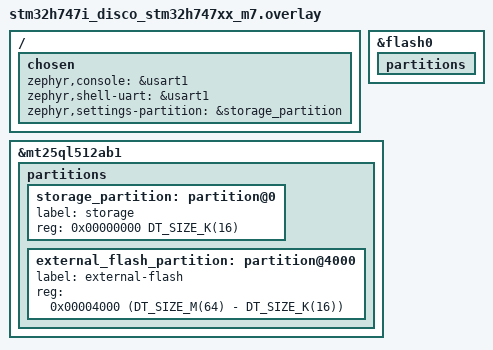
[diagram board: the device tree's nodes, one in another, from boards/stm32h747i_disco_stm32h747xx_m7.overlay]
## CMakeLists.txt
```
cmake_minimum_required(VERSION 3.20.0)
find_package(Zephyr REQUIRED HINTS $ENV{ZEPHYR_BASE})
project(industrial_ethernet)

target_include_directories(app PRIVATE
  src/core
  src/net
  src/protocols/eip
  src/protocols/modbus
  src/ui
  src/web
)

target_sources(app PRIVATE
  src/core/main.c
  src/core/ident.c
  src/net/net_cfg.c
  src/shell/util_cmds.c
  src/protocols/modbus/app_modbus_tcp.c
  src/protocols/modbus/app_modbus_scanner.c
  src/ui/app_lcd.c
  src/web/app_web.c
)

add_subdirectory(src/protocols/eip)
```

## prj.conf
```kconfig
# Phase 1: Network connectivity
CONFIG_NETWORKING=y
CONFIG_NET_IPV4=y
CONFIG_NET_IPV6=y
CONFIG_NET_IPV6_ND=y
CONFIG_NET_IPV6_DAD=y
CONFIG_NET_IPV6_MLD=y
CONFIG_NET_TCP=y
CONFIG_NET_UDP=y
CONFIG_NET_DHCPV4=y
CONFIG_NET_L2_ETHERNET=y
CONFIG_NET_SOCKETS=y
CONFIG_NET_SHELL=n
CONFIG_NET_STATISTICS=n
CONFIG_NET_BUF_POOL_USAGE=n

# Network buffers
CONFIG_NET_PKT_RX_COUNT=16
CONFIG_NET_PKT_TX_COUNT=16
CONFIG_NET_BUF_RX_COUNT=32
CONFIG_NET_BUF_TX_COUNT=32
CONFIG_NET_MAX_CONTEXTS=24
# Modbus, Web, EIP listeners and their concurrent accepted connections.
CONFIG_NET_MAX_CONN=16
# OpENer: 3 listeners + 6 explicit sessions + 1 implicit I/O socket
CONFIG_ZVFS_POLL_MAX=10

# Network events
CONFIG_NET_MGMT_EVENT_INFO=y
CONFIG_NET_MGMT_EVENT_STACK_SIZE=2048
CONFIG_NET_ARP_GRATUITOUS_TRANSMISSION=y

# Modbus TCP server
CONFIG_MODBUS=y
CONFIG_MODBUS_ROLE_SERVER=y
CONFIG_MODBUS_RAW_ADU=y
CONFIG_MODBUS_NUMOF_RAW_ADU=2
CONFIG_MODBUS_FP_EXTENSIONS=n
CONFIG_MODBUS_LOG_LEVEL_INF=y

# Logging
CONFIG_LOG=y
CONFIG_LOG_MODE_IMMEDIATE=y

# Shell
CONFIG_SHELL=y
CONFIG_KERNEL_SHELL=y
CONFIG_REBOOT=y

# Main stack size
CONFIG_MAIN_STACK_SIZE=4096

# GPIO for LED heartbeat
CONFIG_GPIO=y
CONFIG_HWINFO=y

# Settings stored in external QSPI NOR through the settings/NVS backend
CONFIG_SETTINGS=y
CONFIG_NVS=y
CONFIG_SETTINGS_NVS=y
CONFIG_SETTINGS_NVS_SECTOR_COUNT=2
CONFIG_NVS_INIT_BAD_MEMORY_REGION=y
CONFIG_FLASH=y
CONFIG_FLASH_MAP=y
CONFIG_FLASH_PAGE_LAYOUT=y
CONFIG_FLASH_STM32_QSPI=y
```

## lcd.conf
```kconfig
# Phase 5: local LVGL dashboard on the M7-owned DSI display
CONFIG_DISPLAY=y
CONFIG_DISPLAY_LOG_LEVEL_ERR=y
CONFIG_INPUT=y
CONFIG_LVGL=y
CONFIG_LV_Z_MEM_POOL_SIZE=32768
CONFIG_LV_USE_LABEL=y
CONFIG_LV_USE_BAR=y
CONFIG_LV_USE_BUTTON=y
CONFIG_LV_FONT_MONTSERRAT_14=y
CONFIG_LV_FONT_MONTSERRAT_20=y
CONFIG_LV_FONT_MONTSERRAT_24=y
```

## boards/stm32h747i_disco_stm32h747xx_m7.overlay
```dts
/* Phase 1: Ethernet is already enabled in the board DTS.
 * This overlay is a placeholder for future partition layout and peripheral config.
 */

/ {
	chosen {
		zephyr,console = &usart1;
		zephyr,shell-uart = &usart1;
		zephyr,settings-partition = &storage_partition;
	};
};

&flash0 {
	partitions {
		/delete-node/ partition@ff800;
	};
};

/* Store settings in the external QSPI NOR so the full internal flash0 remains
 * available for the M7 application image.
 */
&mt25ql512ab1 {
	partitions {
		/delete-node/ partition@0;

		storage_partition: partition@0 {
			label = "storage";
			reg = <0x00000000 DT_SIZE_K(16)>;
		};

		external_flash_partition: partition@4000 {
			label = "external-flash";
			reg = <0x00004000 (DT_SIZE_M(64) - DT_SIZE_K(16))>;
		};
	};
};
```

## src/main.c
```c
/*
 * Phase 1: DHCP/static IPv4, ping support and LED heartbeat.
 * Target: STM32H747I-DISCO Cortex-M7.
 */

#include <zephyr/kernel.h>
#include <zephyr/net/net_if.h>
#include <zephyr/net/net_mgmt.h>
#include <zephyr/net/net_event.h>
#include <zephyr/net/net_ip.h>
#include <zephyr/drivers/gpio.h>
#include <zephyr/settings/settings.h>
#include <zephyr/logging/log.h>

#include "app_modbus_tcp.h"
#include "net_cfg.h"

LOG_MODULE_REGISTER(main, LOG_LEVEL_INF);

static const struct gpio_dt_spec led = GPIO_DT_SPEC_GET(DT_ALIAS(led0), gpios);
static struct net_mgmt_event_callback mgmt_cb;

static void net_event_handler(struct net_mgmt_event_callback *cb,
			      uint64_t mgmt_event, struct net_if *iface)
{
	struct net_if_config *cfg;
	struct net_if_addr *dhcp_addr = NULL;

	ARG_UNUSED(cb);

	if (mgmt_event != NET_EVENT_IPV4_DHCP_BOUND) {
		return;
	}

	cfg = net_if_get_config(iface);
	for (int i = 0; i < NET_IF_MAX_IPV4_ADDR; i++) {
		struct net_if_addr *ifaddr = &cfg->ip.ipv4->unicast[i].ipv4;

		if (ifaddr->is_used && ifaddr->addr_type == NET_ADDR_DHCP) {
			dhcp_addr = ifaddr;
			break;
		}
	}

	if (dhcp_addr) {
		char addr_str[NET_IPV4_ADDR_LEN];

		net_addr_ntop(AF_INET, &dhcp_addr->address.in_addr,
			      addr_str, sizeof(addr_str));
		LOG_INF("DHCP bound: %s", addr_str);
	}
}

int main(void)
{
	struct net_if *iface;
	int ret;

	LOG_INF("=== H747 Demo Phase 1 ===");

	if (!gpio_is_ready_dt(&led)) {
		LOG_ERR("LED device not ready");
		return -1;
	}
	gpio_pin_configure_dt(&led, GPIO_OUTPUT_ACTIVE);

	net_mgmt_init_event_callback(&mgmt_cb, net_event_handler,
				     NET_EVENT_IPV4_DHCP_BOUND);
	net_mgmt_add_event_callback(&mgmt_cb);

	ret = settings_subsys_init();
	if (ret < 0) {
		LOG_ERR("settings_subsys_init failed: %d", ret);
	} else {
		ret = net_cfg_load();
		if (ret < 0) {
			LOG_ERR("net_cfg_load failed: %d", ret);
		}
	}

	iface = net_if_get_default();
	if (!iface) {
		LOG_ERR("No network interface found");
		return -1;
	}

	ret = net_cfg_apply(iface);
	if (ret < 0) {
		LOG_ERR("net_cfg_apply failed: %d", ret);
	}

	ret = app_modbus_tcp_start();
	if (ret < 0) {
		LOG_ERR("app_modbus_tcp_start failed: %d", ret);
	}

	while (1) {
		gpio_pin_toggle_dt(&led);
		app_modbus_tcp_heartbeat_tick();
		k_msleep(500);
	}

	return 0;
}
```

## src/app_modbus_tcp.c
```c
/*
 * Modbus TCP server.
 *
 * The Zephyr Modbus server handles standard function codes through the
 * callbacks below. TCP framing is provided here through a RAW ADU backend.
 */

#include <errno.h>
#include <string.h>

#include <zephyr/kernel.h>
#include <zephyr/logging/log.h>
#include <zephyr/modbus/modbus.h>
#include <zephyr/net/socket.h>
#include <zephyr/sys/byteorder.h>
#include <zephyr/sys/util.h>

#include "app_modbus_tcp.h"
#include "modbus_map.h"
#include "net_cfg.h"

LOG_MODULE_REGISTER(app_modbus_tcp, LOG_LEVEL_INF);

#define APP_MODBUS_TCP_PORT 502
#define APP_MODBUS_UNIT_ID 1
#define APP_MODBUS_THREAD_STACK_SIZE 4096
#define APP_MODBUS_THREAD_PRIORITY 7

#define APP_MODBUS_FC23_READ_WRITE_REGS 0x17
#define APP_MODBUS_TCP_BACKLOG 2
#define APP_MODBUS_RAW_TIMEOUT_MS 1000

static uint16_t holding_regs[APP_MODBUS_HOLDING_REG_COUNT] = {
	[0] = 0x0747,
	[1] = 1,
};

static struct modbus_adu tcp_adu;
static K_SEM_DEFINE(raw_response_ready, 0, 1);
static int server_iface = -1;
static bool server_started;
static uint16_t connection_count;
static uint16_t heartbeat_counter;
static int16_t last_status;

K_THREAD_STACK_DEFINE(modbus_tcp_stack, APP_MODBUS_THREAD_STACK_SIZE);
static struct k_thread modbus_tcp_thread;
static k_tid_t modbus_tcp_tid;

static uint16_t ipv4_word_msw(const char *ip)
{
	struct in_addr addr;
	uint32_t host_addr;

	if (net_addr_pton(AF_INET, ip, &addr) < 0) {
		return 0;
	}

	host_addr = ntohl(addr.s_addr);
	return (uint16_t)(host_addr >> 16);
}

static uint16_t ipv4_word_lsw(const char *ip)
{
	struct in_addr addr;
	uint32_t host_addr;

	if (net_addr_pton(AF_INET, ip, &addr) < 0) {
		return 0;
	}

	host_addr = ntohl(addr.s_addr);
	return (uint16_t)(host_addr & 0xffffU);
}

static void ipv4_words_to_string(uint16_t msw, uint16_t lsw, char *dst, size_t dst_len)
{
	uint32_t host_addr = ((uint32_t)msw << 16) | lsw;
	struct in_addr addr = {
		.s_addr = htonl(host_addr),
	};

	net_addr_ntop(AF_INET, &addr, dst, dst_len);
}

static void sync_holding_regs_from_saved_cfg(void)
{
	struct net_cfg_data saved;

	if (net_cfg_get_saved(&saved) < 0) {
		return;
	}

	holding_regs[APP_MB_HREG_SIGNATURE] = 0x0747;
	holding_regs[APP_MB_HREG_MODE] = (uint16_t)saved.mode;
	holding_regs[APP_MB_HREG_IP_MSW] = ipv4_word_msw(saved.ip);
	holding_regs[APP_MB_HREG_IP_LSW] = ipv4_word_lsw(saved.ip);
	holding_regs[APP_MB_HREG_MASK_MSW] = ipv4_word_msw(saved.mask);
	holding_regs[APP_MB_HREG_MASK_LSW] = ipv4_word_lsw(saved.mask);
	holding_regs[APP_MB_HREG_GW_MSW] = ipv4_word_msw(saved.gw);
	holding_regs[APP_MB_HREG_GW_LSW] = ipv4_word_lsw(saved.gw);
}

static int apply_holding_regs_command(uint16_t command)
{
	struct net_cfg_data saved = { 0 };
	int ret;

	if (command == APP_MB_CMD_NONE) {
		return 0;
	}

	if (holding_regs[APP_MB_HREG_MODE] > NET_CFG_STATIC) {
		return -EINVAL;
	}

	saved.mode = (enum net_cfg_mode)holding_regs[APP_MB_HREG_MODE];
	ipv4_words_to_string(holding_regs[APP_MB_HREG_IP_MSW],
			     holding_regs[APP_MB_HREG_IP_LSW],
			     saved.ip, sizeof(saved.ip));
	ipv4_words_to_string(holding_regs[APP_MB_HREG_MASK_MSW],
			     holding_regs[APP_MB_HREG_MASK_LSW],
			     saved.mask, sizeof(saved.mask));
	ipv4_words_to_string(holding_regs[APP_MB_HREG_GW_MSW],
			     holding_regs[APP_MB_HREG_GW_LSW],
			     saved.gw, sizeof(saved.gw));

	ret = net_cfg_set_saved(&saved);
	if (ret < 0) {
		return ret;
	}

	if (command == APP_MB_CMD_SAVE_APPLY) {
		ret = net_cfg_apply(NULL);
		if (ret < 0) {
			return ret;
		}
	}

	return 0;
}

static int input_reg_rd(uint16_t addr, uint16_t *reg)
{
	struct net_cfg_data active = { 0 };
	uint32_t uptime_s = (uint32_t)(k_uptime_get() / 1000);

	if (addr >= APP_MODBUS_INPUT_REG_COUNT) {
		return -ENOTSUP;
	}

	(void)net_cfg_get_active(&active);

	switch (addr) {
	case APP_MB_IREG_SIGNATURE:
		*reg = 0x0747;
		break;
	case APP_MB_IREG_MAP_VERSION:
		*reg = APP_MODBUS_MAP_VERSION;
		break;
	case APP_MB_IREG_UPTIME_LSW:
		*reg = (uint16_t)(uptime_s & 0xffffU);
		break;
	case APP_MB_IREG_UPTIME_MSW:
		*reg = (uint16_t)(uptime_s >> 16);
		break;
	case APP_MB_IREG_ACTIVE_MODE:
		*reg = (uint16_t)active.mode;
		break;
	case APP_MB_IREG_LINK_STATUS:
		*reg = net_cfg_link_is_up() ? 1U : 0U;
		break;
	case APP_MB_IREG_IP_MSW:
		*reg = ipv4_word_msw(active.ip);
		break;
	case APP_MB_IREG_IP_LSW:
		*reg = ipv4_word_lsw(active.ip);
		break;
	case APP_MB_IREG_MASK_MSW:
		*reg = ipv4_word_msw(active.mask);
		break;
	case APP_MB_IREG_MASK_LSW:
		*reg = ipv4_word_lsw(active.mask);
		break;
	case APP_MB_IREG_GW_MSW:
		*reg = ipv4_word_msw(active.gw);
		break;
	case APP_MB_IREG_GW_LSW:
		*reg = ipv4_word_lsw(active.gw);
		break;
	case APP_MB_IREG_HEARTBEAT_LSW:
		*reg = heartbeat_counter;
		break;
	case APP_MB_IREG_LAST_STATUS:
		*reg = (uint16_t)last_status;
		break;
	case APP_MB_IREG_CONN_COUNT:
		*reg = connection_count;
		break;
	default:
		*reg = 0;
		break;
	}

	return 0;
}

static int holding_reg_rd(uint16_t addr, uint16_t *reg)
{
	if (addr >= APP_MODBUS_HOLDING_REG_COUNT) {
		return -ENOTSUP;
	}

	sync_holding_regs_from_saved_cfg();
	*reg = holding_regs[addr];
	return 0;
}

static int holding_reg_wr(uint16_t addr, uint16_t reg)
{
	int ret;

	if (addr >= APP_MODBUS_HOLDING_REG_COUNT) {
		return -ENOTSUP;
	}

	holding_regs[addr] = reg;

	if (addr == APP_MB_HREG_COMMAND) {
		ret = apply_holding_regs_command(reg);
		last_status = (int16_t)ret;
		holding_regs[APP_MB_HREG_STATUS] = (uint16_t)ret;
		holding_regs[APP_MB_HREG_COMMAND] = APP_MB_CMD_NONE;

		if (ret == 0) {
			sync_holding_regs_from_saved_cfg();
		}
	}

	return 0;
}

static bool fc23_read_write_holding_regs(const int iface,
					 const struct modbus_adu *const rx_adu,
					 struct modbus_adu *const tx_adu,
					 uint8_t *const excep_code,
					 void *const user_data)
{
	uint16_t read_addr;
	uint16_t read_qty;
	uint16_t write_addr;
	uint16_t write_qty;
	uint8_t write_bytes;
	uint8_t response_bytes;

	ARG_UNUSED(iface);
	ARG_UNUSED(user_data);

	if (rx_adu->length < 9) {
		*excep_code = MODBUS_EXC_ILLEGAL_DATA_VAL;
		return true;
	}

	read_addr = sys_get_be16(&rx_adu->data[0]);
	read_qty = sys_get_be16(&rx_adu->data[2]);
	write_addr = sys_get_be16(&rx_adu->data[4]);
	write_qty = sys_get_be16(&rx_adu->data[6]);
	write_bytes = rx_adu->data[8];

	if (read_qty == 0 || read_qty > 125 ||
	    write_qty == 0 || write_qty > 121 ||
	    write_bytes != write_qty * sizeof(uint16_t) ||
	    rx_adu->length != 9 + write_bytes) {
		*excep_code = MODBUS_EXC_ILLEGAL_DATA_VAL;
		return true;
	}

	for (uint16_t i = 0; i < write_qty; i++) {
		uint16_t reg = sys_get_be16(&rx_adu->data[9 + (i * sizeof(uint16_t))]);

		if (holding_reg_wr(write_addr + i, reg) != 0) {
			*excep_code = MODBUS_EXC_ILLEGAL_DATA_ADDR;
			return true;
		}
	}

	response_bytes = read_qty * sizeof(uint16_t);
	tx_adu->data[0] = response_bytes;
	tx_adu->length = response_bytes + 1;

	for (uint16_t i = 0; i < read_qty; i++) {
		uint16_t reg;

		if (holding_reg_rd(read_addr + i, &reg) != 0) {
			*excep_code = MODBUS_EXC_ILLEGAL_DATA_ADDR;
			return true;
		}

		sys_put_be16(reg, &tx_adu->data[1 + (i * sizeof(uint16_t))]);
	}

	return true;
}

MODBUS_CUSTOM_FC_DEFINE(fc23, fc23_read_write_holding_regs,
			APP_MODBUS_FC23_READ_WRITE_REGS, NULL);

static struct modbus_user_callbacks server_callbacks = {
	.input_reg_rd = input_reg_rd,
	.holding_reg_rd = holding_reg_rd,
	.holding_reg_wr = holding_reg_wr,
};

static int raw_tx_cb(const int iface, const struct modbus_adu *adu, void *user_data)
{
	ARG_UNUSED(iface);
	ARG_UNUSED(user_data);

	tcp_adu.trans_id = adu->trans_id;
	tcp_adu.proto_id = adu->proto_id;
	tcp_adu.length = adu->length;
	tcp_adu.unit_id = adu->unit_id;
	tcp_adu.fc = adu->fc;
	memcpy(tcp_adu.data, adu->data, MIN(adu->length, sizeof(tcp_adu.data)));

	k_sem_give(&raw_response_ready);
	return 0;
}

static const struct modbus_iface_param server_param = {
	.mode = MODBUS_MODE_RAW,
	.server = {
		.user_cb = &server_callbacks,
		.unit_id = APP_MODBUS_UNIT_ID,
	},
	.rawcb = {
		.raw_tx_cb = raw_tx_cb,
		.user_data = NULL,
	},
};

static int init_modbus_server(void)
{
	int ret;

	sync_holding_regs_from_saved_cfg();
	holding_regs[APP_MB_HREG_STATUS] = 0;

	server_iface = modbus_iface_get_by_name("RAW_0");
	if (server_iface < 0) {
		LOG_ERR("Failed to get RAW_0 Modbus interface: %d", server_iface);
		return server_iface;
	}

	ret = modbus_init_server(server_iface, server_param);
	if (ret < 0) {
		LOG_ERR("modbus_init_server failed: %d", ret);
		return ret;
	}

	ret = modbus_register_user_fc(server_iface, &modbus_cfg_fc23);
	if (ret < 0) {
		LOG_ERR("Failed to register FC23 handler: %d", ret);
		return ret;
	}

	LOG_INF("Modbus server ready: unit=%d, holding=%d, input=%d",
		APP_MODBUS_UNIT_ID, APP_MODBUS_HOLDING_REG_COUNT,
		APP_MODBUS_INPUT_REG_COUNT);
	return 0;
}

static int send_all(int client, const void *buf, size_t len)
{
	const uint8_t *cursor = buf;

	while (len > 0) {
		int ret = zsock_send(client, cursor, len, 0);

		if (ret < 0) {
			return -errno;
		}
		if (ret == 0) {
			return -ENOTCONN;
		}

		cursor += ret;
		len -= ret;
	}

	return 0;
}

static int send_modbus_reply(int client, const struct modbus_adu *adu)
{
	uint8_t header[MODBUS_MBAP_AND_FC_LENGTH];
	int ret;

	modbus_raw_put_header(adu, header);

	ret = send_all(client, header, sizeof(header));
	if (ret < 0) {
		return ret;
	}

	ret = send_all(client, adu->data, adu->length);
	if (ret < 0) {
		return ret;
	}

	return 0;
}

static int handle_modbus_connection(int client)
{
	uint8_t header[MODBUS_MBAP_AND_FC_LENGTH];
	int ret;

	ret = zsock_recv(client, header, sizeof(header), ZSOCK_MSG_WAITALL);
	if (ret <= 0) {
		return ret == 0 ? -ENOTCONN : -errno;
	}

	modbus_raw_get_header(&tcp_adu, header);
	if (tcp_adu.length > sizeof(tcp_adu.data)) {
		return -EMSGSIZE;
	}

	ret = zsock_recv(client, tcp_adu.data, tcp_adu.length, ZSOCK_MSG_WAITALL);
	if (ret <= 0) {
		return ret == 0 ? -ENOTCONN : -errno;
	}

	k_sem_reset(&raw_response_ready);
	ret = modbus_raw_submit_rx(server_iface, &tcp_adu);
	if (ret < 0) {
		LOG_ERR("modbus_raw_submit_rx failed: %d", ret);
		return ret;
	}

	if (k_sem_take(&raw_response_ready, K_MSEC(APP_MODBUS_RAW_TIMEOUT_MS)) != 0) {
		LOG_ERR("Modbus response timeout");
		modbus_raw_set_server_failure(&tcp_adu);
	}

	return send_modbus_reply(client, &tcp_adu);
}

static void modbus_tcp_thread_fn(void *arg1, void *arg2, void *arg3)
{
	struct sockaddr_in bind_addr = {
		.sin_family = AF_INET,
		.sin_addr.s_addr = htonl(INADDR_ANY),
		.sin_port = htons(APP_MODBUS_TCP_PORT),
	};
	int server;

	ARG_UNUSED(arg1);
	ARG_UNUSED(arg2);
	ARG_UNUSED(arg3);

	server = zsock_socket(AF_INET, SOCK_STREAM, IPPROTO_TCP);
	if (server < 0) {
		LOG_ERR("socket failed: %d", errno);
		return;
	}

	if (zsock_bind(server, (struct net_sockaddr *)&bind_addr, sizeof(bind_addr)) < 0) {
		LOG_ERR("bind port %d failed: %d", APP_MODBUS_TCP_PORT, errno);
		(void)zsock_close(server);
		return;
	}

	if (zsock_listen(server, APP_MODBUS_TCP_BACKLOG) < 0) {
		LOG_ERR("listen failed: %d", errno);
		(void)zsock_close(server);
		return;
	}

	LOG_INF("Modbus TCP listening on port %d", APP_MODBUS_TCP_PORT);

	while (true) {
		struct sockaddr_in client_addr;
		net_socklen_t client_addr_len = sizeof(client_addr);
		int client;
		int ret;

		client = zsock_accept(server, (struct net_sockaddr *)&client_addr,
				      &client_addr_len);
		if (client < 0) {
			LOG_ERR("accept failed: %d", errno);
			continue;
		}

		connection_count++;
		do {
			ret = handle_modbus_connection(client);
		} while (ret == 0);

		(void)zsock_close(client);
	}
}

int app_modbus_tcp_start(void)
{
	int ret;

	if (server_started) {
		return 0;
	}

	ret = init_modbus_server();
	if (ret < 0) {
		return ret;
	}

	modbus_tcp_tid = k_thread_create(&modbus_tcp_thread, modbus_tcp_stack,
					 K_THREAD_STACK_SIZEOF(modbus_tcp_stack),
					 modbus_tcp_thread_fn,
					 NULL, NULL, NULL,
					 APP_MODBUS_THREAD_PRIORITY, 0, K_NO_WAIT);
	k_thread_name_set(modbus_tcp_tid, "modbus_tcp");

	server_started = true;
	return 0;
}

void app_modbus_tcp_heartbeat_tick(void)
{
	heartbeat_counter++;
}
```

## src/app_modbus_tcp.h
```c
#ifndef APP_MODBUS_TCP_H_
#define APP_MODBUS_TCP_H_

int app_modbus_tcp_start(void);
void app_modbus_tcp_heartbeat_tick(void);

#endif /* APP_MODBUS_TCP_H_ */
```

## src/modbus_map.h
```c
#ifndef MODBUS_MAP_H_
#define MODBUS_MAP_H_

#define APP_MODBUS_MAP_VERSION 1

#define APP_MODBUS_HOLDING_REG_COUNT 32
#define APP_MODBUS_INPUT_REG_COUNT 16

#define APP_MB_HREG_SIGNATURE 0
#define APP_MB_HREG_MODE 1
#define APP_MB_HREG_IP_MSW 2
#define APP_MB_HREG_IP_LSW 3
#define APP_MB_HREG_MASK_MSW 4
#define APP_MB_HREG_MASK_LSW 5
#define APP_MB_HREG_GW_MSW 6
#define APP_MB_HREG_GW_LSW 7
#define APP_MB_HREG_COMMAND 8
#define APP_MB_HREG_STATUS 9

#define APP_MB_IREG_SIGNATURE 0
#define APP_MB_IREG_MAP_VERSION 1
#define APP_MB_IREG_UPTIME_LSW 2
#define APP_MB_IREG_UPTIME_MSW 3
#define APP_MB_IREG_ACTIVE_MODE 4
#define APP_MB_IREG_LINK_STATUS 5
#define APP_MB_IREG_IP_MSW 6
#define APP_MB_IREG_IP_LSW 7
#define APP_MB_IREG_MASK_MSW 8
#define APP_MB_IREG_MASK_LSW 9
#define APP_MB_IREG_GW_MSW 10
#define APP_MB_IREG_GW_LSW 11
#define APP_MB_IREG_HEARTBEAT_LSW 12
#define APP_MB_IREG_LAST_STATUS 13
#define APP_MB_IREG_CONN_COUNT 14
#define APP_MB_IREG_RESERVED 15

#define APP_MB_CMD_NONE 0
#define APP_MB_CMD_SAVE 1
#define APP_MB_CMD_SAVE_APPLY 2

#endif /* MODBUS_MAP_H_ */
```

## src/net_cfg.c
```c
/*
 * Network configuration: DHCP/static IPv4, shell commands and settings storage.
 */

#include <zephyr/kernel.h>
#include <zephyr/shell/shell.h>
#include <zephyr/settings/settings.h>
#include <zephyr/net/net_if.h>
#include <zephyr/net/net_ip.h>
#include <zephyr/net/dhcpv4.h>
#include <zephyr/logging/log.h>
#include <errno.h>

#include "net_cfg.h"

LOG_MODULE_REGISTER(net_cfg, LOG_LEVEL_INF);

#define NET_CFG_DEFAULT_IP   "192.168.0.3"
#define NET_CFG_DEFAULT_MASK "255.255.255.0"
#define NET_CFG_DEFAULT_GW   "192.168.0.1"
#define NET_CFG_STORE_KEY    "net_cfg/blob"
#define NET_CFG_STORE_MAGIC  0x4e455443U
#define NET_CFG_STORE_VER    1U

struct net_cfg_store {
	uint32_t magic;
	uint8_t version;
	uint8_t mode;
	char ip[16];
	char mask[16];
	char gw[16];
};

static struct net_cfg_data cfg = {
	.mode = NET_CFG_DHCP,
	.ip = NET_CFG_DEFAULT_IP,
	.mask = NET_CFG_DEFAULT_MASK,
	.gw = NET_CFG_DEFAULT_GW,
};

static K_MUTEX_DEFINE(cfg_lock);
static net_cfg_change_cb_t change_cb;

static void net_cfg_notify_changed(void)
{
	if (change_cb) {
		change_cb();
	}
}

static void net_cfg_restore_defaults(void)
{
	cfg.mode = NET_CFG_DHCP;
	snprintk(cfg.ip, sizeof(cfg.ip), "%s", NET_CFG_DEFAULT_IP);
	snprintk(cfg.mask, sizeof(cfg.mask), "%s", NET_CFG_DEFAULT_MASK);
	snprintk(cfg.gw, sizeof(cfg.gw), "%s", NET_CFG_DEFAULT_GW);
}

static bool net_cfg_is_ipv4_string(const char *value)
{
	struct in_addr tmp;

	return net_addr_pton(AF_INET, value, &tmp) == 0;
}

static bool net_cfg_store_is_valid(const struct net_cfg_store *store)
{
	return store->magic == NET_CFG_STORE_MAGIC &&
	       store->version == NET_CFG_STORE_VER &&
	       net_cfg_is_ipv4_string(store->ip) &&
	       net_cfg_is_ipv4_string(store->mask) &&
	       net_cfg_is_ipv4_string(store->gw);
}

static int net_cfg_save(const struct net_cfg_data *data)
{
	struct net_cfg_store store = {
		.magic = NET_CFG_STORE_MAGIC,
		.version = NET_CFG_STORE_VER,
		.mode = data->mode,
	};

	snprintk(store.ip, sizeof(store.ip), "%s", data->ip);
	snprintk(store.mask, sizeof(store.mask), "%s", data->mask);
	snprintk(store.gw, sizeof(store.gw), "%s", data->gw);

	return settings_save_one(NET_CFG_STORE_KEY, &store, sizeof(store));
}

static void net_cfg_copy(struct net_cfg_data *dst, const struct net_cfg_data *src)
{
	dst->mode = src->mode;
	snprintk(dst->ip, sizeof(dst->ip), "%s", src->ip);
	snprintk(dst->mask, sizeof(dst->mask), "%s", src->mask);
	snprintk(dst->gw, sizeof(dst->gw), "%s", src->gw);
}

static int net_cfg_validate(const struct net_cfg_data *data)
{
	if (!data) {
		return -EINVAL;
	}

	if (data->mode != NET_CFG_DHCP && data->mode != NET_CFG_STATIC) {
		return -EINVAL;
	}

	if (!net_cfg_is_ipv4_string(data->ip) ||
	    !net_cfg_is_ipv4_string(data->mask) ||
	    !net_cfg_is_ipv4_string(data->gw)) {
		return -EINVAL;
	}

	return 0;
}

static int net_cfg_load_string(const char *name, char *dst, size_t dst_size)
{
	ssize_t len;

	len = settings_load_one(name, dst, dst_size - 1);
	if (len == -ENOENT || len == 0) {
		return 0;
	}
	if (len < 0) {
		return (int)len;
	}
	if ((size_t)len >= dst_size) {
		return -EINVAL;
	}

	dst[len] = '\0';
	return 0;
}

int net_cfg_load(void)
{
	struct net_cfg_store store;
	uint8_t mode;
	ssize_t len;
	int ret;

	len = settings_load_one(NET_CFG_STORE_KEY, &store, sizeof(store));
	if (len == sizeof(store) && net_cfg_store_is_valid(&store)) {
		cfg.mode = (store.mode == NET_CFG_STATIC) ? NET_CFG_STATIC : NET_CFG_DHCP;
		snprintk(cfg.ip, sizeof(cfg.ip), "%s", store.ip);
		snprintk(cfg.mask, sizeof(cfg.mask), "%s", store.mask);
		snprintk(cfg.gw, sizeof(cfg.gw), "%s", store.gw);
		goto loaded;
	}

	if (len >= 0) {
		LOG_ERR("Invalid persisted config blob, restoring defaults");
		net_cfg_restore_defaults();

		ret = net_cfg_save(&cfg);
		if (ret < 0) {
			LOG_ERR("Failed to save default config: %d", ret);
			return ret;
		}

		goto loaded;
	}

	if (len != -ENOENT) {
		return (int)len;
	}

	/* One-time migration path for older builds that used separate keys. */
	len = settings_load_one("net_cfg/mode", &mode, sizeof(mode));
	if (len == sizeof(mode)) {
		cfg.mode = (mode == NET_CFG_STATIC) ? NET_CFG_STATIC : NET_CFG_DHCP;
	} else if (len < 0 && len != -ENOENT) {
		return (int)len;
	}

	ret = net_cfg_load_string("net_cfg/ip", cfg.ip, sizeof(cfg.ip));
	if (ret < 0) {
		return ret;
	}

	ret = net_cfg_load_string("net_cfg/mask", cfg.mask, sizeof(cfg.mask));
	if (ret < 0) {
		return ret;
	}

	ret = net_cfg_load_string("net_cfg/gw", cfg.gw, sizeof(cfg.gw));
	if (ret < 0) {
		return ret;
	}

	if (!net_cfg_is_ipv4_string(cfg.ip) ||
	    !net_cfg_is_ipv4_string(cfg.mask) ||
	    !net_cfg_is_ipv4_string(cfg.gw)) {
		LOG_ERR("Invalid persisted config, restoring defaults");
		net_cfg_restore_defaults();
	}

	ret = net_cfg_save(&cfg);
	if (ret < 0) {
		LOG_ERR("Failed to migrate config: %d", ret);
		return ret;
	}

	LOG_INF("Config migrated to blob storage");

loaded:
	LOG_INF("Loaded config: mode=%s ip=%s mask=%s gw=%s",
		cfg.mode == NET_CFG_STATIC ? "static" : "dhcp",
		cfg.ip, cfg.mask, cfg.gw);

	return 0;
}

int net_cfg_start(struct net_if *iface)
{
	struct net_cfg_data active_cfg;

	net_cfg_get_saved(&active_cfg);

	if (!iface) {
		iface = net_if_get_default();
	}
	if (!iface) {
		LOG_ERR("No network interface");
		return -ENODEV;
	}

	if (active_cfg.mode == NET_CFG_STATIC) {
		struct in_addr addr, mask, gw;
		struct net_if_addr *ifaddr;

		if (net_addr_pton(AF_INET, active_cfg.ip, &addr) < 0) {
			LOG_ERR("Invalid IP: %s", active_cfg.ip);
			return -EINVAL;
		}
		if (net_addr_pton(AF_INET, active_cfg.mask, &mask) < 0) {
			LOG_ERR("Invalid mask: %s", active_cfg.mask);
			return -EINVAL;
		}
		if (net_addr_pton(AF_INET, active_cfg.gw, &gw) < 0) {
			LOG_ERR("Invalid gateway: %s", active_cfg.gw);
			return -EINVAL;
		}

		ifaddr = net_if_ipv4_addr_add(iface, &addr, NET_ADDR_MANUAL, 0);
		if (!ifaddr) {
			LOG_ERR("Failed to add static IP address: %s", active_cfg.ip);
			return -ENOSPC;
		}

		if (!net_if_ipv4_set_netmask_by_addr(iface, &addr, &mask)) {
			LOG_ERR("Failed to set netmask: %s", active_cfg.mask);
			return -EIO;
		}
		net_if_ipv4_set_gw(iface, &gw);

		LOG_INF("Static IP configured: %s / %s gw %s",
			active_cfg.ip, active_cfg.mask, active_cfg.gw);
	} else {
		net_dhcpv4_start(iface);
		LOG_INF("DHCP client started, waiting for lease...");
	}

	return 0;
}

int net_cfg_get_saved(struct net_cfg_data *out)
{
	if (!out) {
		return -EINVAL;
	}

	k_mutex_lock(&cfg_lock, K_FOREVER);
	net_cfg_copy(out, &cfg);
	k_mutex_unlock(&cfg_lock);
	return 0;
}

int net_cfg_set_saved(const struct net_cfg_data *in)
{
	int ret;

	ret = net_cfg_validate(in);
	if (ret < 0) {
		return ret;
	}

	ret = net_cfg_save(in);
	if (ret < 0) {
		return ret;
	}

	k_mutex_lock(&cfg_lock, K_FOREVER);
	net_cfg_copy(&cfg, in);
	k_mutex_unlock(&cfg_lock);

	net_cfg_notify_changed();
	return 0;
}

void net_cfg_register_change_cb(net_cfg_change_cb_t cb)
{
	change_cb = cb;
}

int net_cfg_get_active(struct net_cfg_data *out)
{
	struct net_if *iface;
	struct net_if_config *if_cfg;
	struct net_in_addr netmask;
	struct net_in_addr gw;
	struct net_if_addr *selected = NULL;
	enum net_cfg_mode mode;

	if (!out) {
		return -EINVAL;
	}

	net_cfg_get_saved(out);
	mode = out->mode;

	iface = net_if_get_default();
	if (!iface) {
		return -ENODEV;
	}

	if_cfg = net_if_get_config(iface);
	if (!if_cfg || !if_cfg->ip.ipv4) {
		return -ENODATA;
	}

	for (int i = 0; i < NET_IF_MAX_IPV4_ADDR; i++) {
		struct net_if_addr *ifaddr = &if_cfg->ip.ipv4->unicast[i].ipv4;

		if (!ifaddr->is_used) {
			continue;
		}

		if (ifaddr->addr_type == NET_ADDR_DHCP) {
			selected = ifaddr;
			mode = NET_CFG_DHCP;
			break;
		}

		if (!selected && ifaddr->addr_type == NET_ADDR_MANUAL) {
			selected = ifaddr;
			mode = NET_CFG_STATIC;
		}
	}

	out->mode = mode;

	if (!selected) {
		snprintk(out->ip, sizeof(out->ip), "%s", "0.0.0.0");
		snprintk(out->mask, sizeof(out->mask), "%s", "0.0.0.0");
		snprintk(out->gw, sizeof(out->gw), "%s", "0.0.0.0");
		return 0;
	}

	net_addr_ntop(AF_INET, &selected->address.in_addr, out->ip, sizeof(out->ip));
	netmask = net_if_ipv4_get_netmask_by_addr(iface, &selected->address.in_addr);
	gw = net_if_ipv4_get_gw(iface);
	net_addr_ntop(AF_INET, &netmask, out->mask, sizeof(out->mask));
	net_addr_ntop(AF_INET, &gw, out->gw, sizeof(out->gw));

	return 0;
}

bool net_cfg_link_is_up(void)
{
	struct net_if *iface = net_if_get_default();

	if (!iface) {
		return false;
	}

	return net_if_is_up(iface) && net_if_is_carrier_ok(iface);
}

static int cmd_net_cfg_show(const struct shell *sh, size_t argc, char **argv)
{
	struct net_cfg_data saved;

	ARG_UNUSED(argc);
	ARG_UNUSED(argv);

	net_cfg_get_saved(&saved);

	shell_print(sh, "Mode    : %s", saved.mode == NET_CFG_DHCP ? "dhcp" : "static");
	shell_print(sh, "IP      : %s", saved.ip);
	shell_print(sh, "Netmask : %s", saved.mask);
	shell_print(sh, "Gateway : %s", saved.gw);
	return 0;
}

static int cmd_net_cfg_dhcp(const struct shell *sh, size_t argc, char **argv)
{
	struct net_cfg_data saved;
	int ret;

	ARG_UNUSED(argc);
	ARG_UNUSED(argv);

	net_cfg_get_saved(&saved);
	saved.mode = NET_CFG_DHCP;

	ret = net_cfg_set_saved(&saved);
	if (ret < 0) {
		shell_error(sh, "Failed to save config: %d", ret);
		return ret;
	}

	shell_print(sh, "Mode set to DHCP. Reboot to activate.");
	return 0;
}

static int cmd_net_cfg_static(const struct shell *sh, size_t argc, char **argv)
{
	struct net_cfg_data saved;
	struct in_addr tmp;
	int ret;

	if (argc < 2) {
		shell_print(sh, "Usage: ip static <ip> [mask] [gateway]");
		shell_print(sh, "  e.g: ip static 192.168.1.3 255.255.255.0 192.168.1.1");
		return -EINVAL;
	}

	if (net_addr_pton(AF_INET, argv[1], &tmp) < 0) {
		shell_error(sh, "Invalid IP address: %s", argv[1]);
		return -EINVAL;
	}

	net_cfg_get_saved(&saved);
	snprintk(saved.ip, sizeof(saved.ip), "%s", argv[1]);

	if (argc >= 3) {
		if (net_addr_pton(AF_INET, argv[2], &tmp) < 0) {
			shell_error(sh, "Invalid netmask: %s", argv[2]);
			return -EINVAL;
		}
		snprintk(saved.mask, sizeof(saved.mask), "%s", argv[2]);
	}

	if (argc >= 4) {
		if (net_addr_pton(AF_INET, argv[3], &tmp) < 0) {
			shell_error(sh, "Invalid gateway: %s", argv[3]);
			return -EINVAL;
		}
		snprintk(saved.gw, sizeof(saved.gw), "%s", argv[3]);
	}

	saved.mode = NET_CFG_STATIC;
	ret = net_cfg_set_saved(&saved);
	if (ret < 0) {
		shell_error(sh, "Failed to save config: %d", ret);
		return ret;
	}

	shell_print(sh, "Static IP saved: %s / %s gw %s", saved.ip, saved.mask, saved.gw);
	shell_print(sh, "Reboot to activate.");
	return 0;
}

SHELL_STATIC_SUBCMD_SET_CREATE(net_cfg_cmds,
	SHELL_CMD(show, NULL, "Show current network config", cmd_net_cfg_show),
	SHELL_CMD(dhcp, NULL, "Switch to DHCP mode", cmd_net_cfg_dhcp),
	SHELL_CMD(static, NULL, "Set static IP: static <ip> [mask] [gw]", cmd_net_cfg_static),
	SHELL_SUBCMD_SET_END
);

SHELL_CMD_REGISTER(ip, &net_cfg_cmds, "Network IP configuration", NULL);
```

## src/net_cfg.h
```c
#ifndef NET_CFG_H_
#define NET_CFG_H_

#include <stdbool.h>
#include <zephyr/net/net_if.h>

enum net_cfg_mode {
	NET_CFG_DHCP = 0,
	NET_CFG_STATIC = 1,
};

struct net_cfg_data {
	enum net_cfg_mode mode;
	char ip[16];
	char mask[16];
	char gw[16];
};

typedef void (*net_cfg_change_cb_t)(void);

int net_cfg_load(void);
int net_cfg_start(struct net_if *iface);
int net_cfg_get_saved(struct net_cfg_data *out);
int net_cfg_set_saved(const struct net_cfg_data *in);
int net_cfg_get_active(struct net_cfg_data *out);
void net_cfg_register_change_cb(net_cfg_change_cb_t cb);
bool net_cfg_link_is_up(void);

#endif /* NET_CFG_H_ */
```
